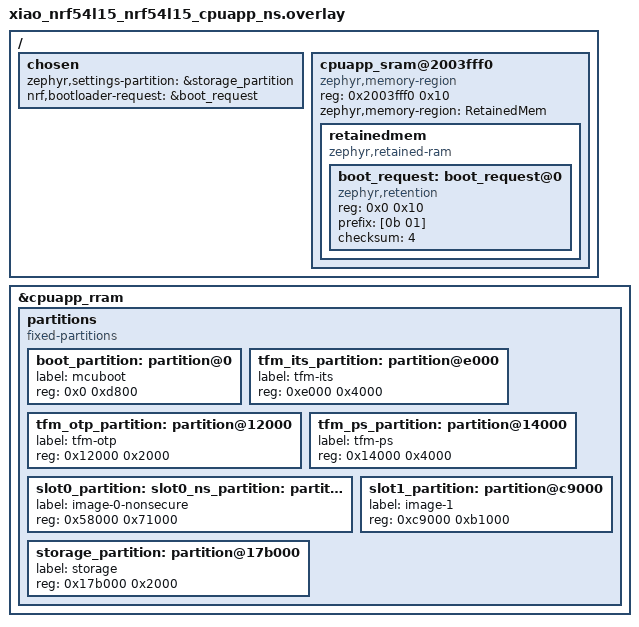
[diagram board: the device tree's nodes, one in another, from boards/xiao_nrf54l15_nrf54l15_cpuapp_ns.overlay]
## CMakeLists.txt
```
#
# Copyright (c) 2026
#
# SPDX-License-Identifier: LicenseRef-Nordic-5-Clause
#

cmake_minimum_required(VERSION 3.20.0)

find_package(Zephyr REQUIRED HINTS $ENV{ZEPHYR_BASE})
project(sap_demo)

target_sources(app PRIVATE
  src/main.c
  src/demo_credentials.c
)

target_sources_ifdef(CONFIG_SAP_ROLE_CENTRAL app PRIVATE src/sap_central.c)
target_sources_ifdef(CONFIG_SAP_ROLE_PERIPHERAL app PRIVATE src/sap_peripheral.c)
target_include_directories(app PRIVATE src)

if(CONFIG_SAP_DEMO_DFU_CLIENT)
  target_include_directories(app PRIVATE
    ${ZEPHYR_BASE}/subsys/mgmt/mcumgr/util/include
  )
  target_sources(app PRIVATE
    ${ZEPHYR_BASE}/subsys/mgmt/mcumgr/util/src/zcbor_bulk.c
  )
endif()

if(CONFIG_SAP_DEMO_DFU_SERVER AND CONFIG_NRF_MCUBOOT_BOOT_REQUEST)
  target_include_directories(app PRIVATE
    ${WEST_TOPDIR}/bootloader/mcuboot/boot/bootutil/include
    ${WEST_TOPDIR}/bootloader/mcuboot/boot/zephyr/include
  )
endif()
```

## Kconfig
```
#
# Copyright (c) 2026
#
# SPDX-License-Identifier: LicenseRef-Nordic-5-Clause
#

# Work around Kconfig's lack of commas in macro arguments.
DT_CHOSEN_Z_SHELL_UART := zephyr,shell-uart

mainmenu "Secure Application Pairing Demo"

source "Kconfig.zephyr"

menu "SAP demo configuration"

choice SAP_ROLE
	prompt "SAP role"
	default SAP_ROLE_CENTRAL

config SAP_ROLE_CENTRAL
	bool "Root node"
	select BT_CENTRAL
	select BT_OBSERVER
	select BT_GATT_CLIENT
	select BT_GATT_DM
	select BT_PERIPHERAL

config SAP_ROLE_PERIPHERAL
	bool "Leaf node"
	select BT_PERIPHERAL

endchoice

config SAP_EXPECTED_GROUP_ID
	hex "Expected SAP group identifier"
	default 0x2A

config SAP_ALLOWED_CENTRAL_ID
	int "Allowed central device identifier"
	range 0 255
	default 0

config SAP_UPSTREAM_ALLOWED_CENTRAL_ID
	int "Allowed upstream controller identifier"
	range 0 255
	default 42
	depends on SAP_ROLE_CENTRAL
	help
	  Device identifier that the root node accepts on its upstream SAP
	  controller link. The default is used by the Bleak host demo script.

config SAP_REQUIRE_BLE_ENCRYPTION
	bool "Require BLE link encryption before SAP"
	default n if BOARD_NRF54L15BSIM
	default y
	help
	  Keep BLE SMP/link encryption as a prerequisite for SAP when the target
	  supports it reliably. On the nrf54l15bsim sample target this defaults
	  to disabled because local BabbleSim validation could not complete the
	  BLE security procedure reliably on that simulator target. The sample
	  still exercises SAP mutual authentication and SAP-level AES-CCM
	  transport protection there.

config SAP_UPSTREAM_REQUIRE_BLE_ENCRYPTION
	bool "Require BLE link encryption on the root upstream controller link"
	depends on SAP_ROLE_CENTRAL
	default y
	help
	  Keep BLE SMP/link encryption as a prerequisite for the root node's
	  upstream SAP controller link. Disable this only for interop demos where
	  the external controller stack cannot complete BLE security reliably and
	  you still want to demonstrate SAP mutual authentication plus SAP-level
	  encrypted transport on that upstream link.

config SAP_USE_BLE_SC_OOB_PAIRING
	bool "Use in-band exchanged BLE Secure Connections OOB for post-auth transport"
	depends on BT_SMP
	default n
	help
	  Prototype a CBAP-like transport flow for root-to-leaf links. SAP still
	  performs certificate-based authentication, but the authenticated nodes
	  exchange LE Secure Connections OOB data during the SAP handshake, then
	  upgrade the BLE link to Security Level 4 and rely on the BLE stack for
	  transport encryption. SAP application payloads then travel as plaintext
	  over the authenticated encrypted BLE link instead of using SAP AES-CCM
	  on every packet. The root's upstream controller link remains on the
	  original SAP encrypted transport path.

config SAP_SHELL
	bool "Enable SAP shell commands"
	default y if !BOARD_NRF54L15BSIM
	default n if BOARD_NRF54L15BSIM
	select SHELL
	select SHELL_VT100_COLORS
	depends on $(dt_chosen_enabled,$(DT_CHOSEN_Z_SHELL_UART)) || BOARD_NRF54L15BSIM
	help
	  Enable a UART shell with SAP demo commands. The central build can list
	  peers and send secure text to one peer or all peers. The peripheral
	  build can send secure text to the connected central. Boards without a
	  non-secure ``zephyr,shell-uart`` chosen node leave the shell disabled
	  by default so the demo can still run without a UART.

if SAP_SHELL

config SHELL_STACK_SIZE
	default 8192

config SHELL_CMD_BUFF_SIZE
	default 256

config SHELL_ARGC_MAX
	default 16

config SHELL_BACKEND_SERIAL_TX_RING_BUFFER_SIZE
	default 1024

endif

config SAP_DK_IO
	bool "Enable DK button and LED demo IO"
	depends on BOARD_NRF54L15DK_NRF54L15_CPUAPP || \
		BOARD_NRF54L15DK_NRF54L15_CPUAPP_NS
	default y
	select DK_LIBRARY
	help
	  Enable the Nordic DK buttons and LEDs for the SAP demo. On the
	  peripheral, Button 1 sends a secure button-state event. On the
	  central, peripherals 1..4 map to LEDs 1..4. Additional peripherals
	  remain authenticated but do not receive an LED assignment.

config SAP_DEMO_PERIPHERAL_ID
	int "Hardware peripheral device identifier"
	depends on SAP_ROLE_PERIPHERAL && !BOARD_NRF54L15BSIM
	range 1 4
	default 1
	help
	  Select which demo peripheral credential this hardware build should use.
	  The sample contains four provisioned peripheral identities with device
	  IDs 1..4. Build each real peripheral with a different value so the
	  central can authenticate and track them as distinct SAP peers.

config SAP_DEMO_GATED_DFU_SERVICE
	bool "Expose gated MCUmgr DFU SMP service after SAP"
	default y if !BOARD_NRF54L15BSIM
	default n if BOARD_NRF54L15BSIM
	help
	  Demonstrate how SAP can hide the standard Bluetooth MCUmgr SMP/DFU
	  service until application-layer authentication succeeds. On hardware,
	  the central then verifies the service by sending an MCUmgr OS echo
	  request after SAP completes.

config SAP_DEMO_DFU_CLIENT
	bool
	default y if SAP_ROLE_CENTRAL && SAP_DEMO_GATED_DFU_SERVICE
	select BT_DFU_SMP
	select ZCBOR

config SAP_DEMO_DFU_SERVER
	bool
	default y if SAP_ROLE_PERIPHERAL && SAP_DEMO_GATED_DFU_SERVICE
	select CRC
	select IMG_MANAGER
	select MCUMGR
	select MCUMGR_GRP_IMG
	select MCUMGR_GRP_OS
	select MCUMGR_TRANSPORT_BT
	select MCUMGR_TRANSPORT_BT_DYNAMIC_SVC_REGISTRATION
	select NET_BUF
	select STREAM_FLASH
	select ZCBOR

config SAP_DEMO_LED_PATTERN_ID
	int "Leaf status LED pattern identifier"
	range 1 2
	default 1
	depends on SAP_ROLE_PERIPHERAL
	help
	  Distinguishes visible leaf firmware variants for the DFU demo. Pattern
	  1 is the default image. Pattern 2 is intended for the post-DFU image
	  so the result is obvious on-device.

endmenu
```

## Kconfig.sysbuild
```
#
# Copyright (c) 2026
#
# SPDX-License-Identifier: LicenseRef-Nordic-5-Clause
#

choice BOOTLOADER
	default BOOTLOADER_MCUBOOT if BOARD_XIAO_NRF54L15
endchoice

if BOOTLOADER_MCUBOOT

choice MCUBOOT_MODE
	default MCUBOOT_MODE_DIRECT_XIP if BOARD_XIAO_NRF54L15
endchoice

config PM_EXTERNAL_FLASH_MCUBOOT_SECONDARY
	default y if BOARD_NRF54L15DK

config PM_OVERRIDE_EXTERNAL_DRIVER_CHECK
	default y if BOARD_NRF54L15DK

endif

source "share/sysbuild/Kconfig"
```

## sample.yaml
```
sample:
  name: Secure Application Pairing
tests:
  sample.bluetooth.sap.central:
    build_only: true
    platform_allow:
      - nrf54l15bsim/nrf54l15/cpuapp
      - nrf54l15dk/nrf54l15/cpuapp
      - nrf54l15dk/nrf54l15/cpuapp/ns
      - xiao_nrf54l15/nrf54l15/cpuapp
      - xiao_nrf54l15/nrf54l15/cpuapp/ns
    integration_platforms:
      - nrf54l15bsim/nrf54l15/cpuapp
      - nrf54l15dk/nrf54l15/cpuapp
      - nrf54l15dk/nrf54l15/cpuapp/ns
      - xiao_nrf54l15/nrf54l15/cpuapp
      - xiao_nrf54l15/nrf54l15/cpuapp/ns
    tags:
      - bluetooth
      - crypto
  sample.bluetooth.sap.peripheral:
    build_only: true
    extra_args: EXTRA_CONF_FILE=peripheral.conf
    platform_allow:
      - nrf54l15bsim/nrf54l15/cpuapp
      - nrf54l15dk/nrf54l15/cpuapp
      - nrf54l15dk/nrf54l15/cpuapp/ns
      - xiao_nrf54l15/nrf54l15/cpuapp
      - xiao_nrf54l15/nrf54l15/cpuapp/ns
    integration_platforms:
      - nrf54l15bsim/nrf54l15/cpuapp
      - nrf54l15dk/nrf54l15/cpuapp
      - nrf54l15dk/nrf54l15/cpuapp/ns
      - xiao_nrf54l15/nrf54l15/cpuapp
      - xiao_nrf54l15/nrf54l15/cpuapp/ns
    tags:
      - bluetooth
      - crypto
```

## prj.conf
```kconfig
#
# Copyright (c) 2026
#
# SPDX-License-Identifier: LicenseRef-Nordic-5-Clause
#

CONFIG_SYS_CLOCK_TICKS_PER_SEC=1000

CONFIG_SAP=y
CONFIG_BT=y
CONFIG_BT_SMP=y
CONFIG_BT_SMP_ENFORCE_MITM=n
CONFIG_BT_PRIVACY=y
CONFIG_BT_DEVICE_NAME="SAP"
CONFIG_BT_DEVICE_NAME_DYNAMIC=y
CONFIG_BT_MAX_CONN=4
CONFIG_BT_MAX_PAIRED=8
CONFIG_BT_RX_STACK_SIZE=8192
CONFIG_BT_LONG_WQ_STACK_SIZE=4096
CONFIG_BT_L2CAP_TX_MTU=300
CONFIG_BT_L2CAP_TX_FRAG_COUNT=6
CONFIG_BT_BUF_ACL_RX_SIZE=304
CONFIG_BT_BUF_ACL_TX_SIZE=251
CONFIG_BT_GATT_DYNAMIC_DB=y
CONFIG_BT_GATT_SERVICE_CHANGED=y

CONFIG_LOG=y
CONFIG_LOG_MODE_IMMEDIATE=y

CONFIG_FLASH=y
CONFIG_FLASH_PAGE_LAYOUT=y
CONFIG_FLASH_MAP=y
CONFIG_NVS=y
CONFIG_SETTINGS=y
CONFIG_SETTINGS_NVS=y
CONFIG_BT_SETTINGS=y

CONFIG_MAIN_STACK_SIZE=8192
CONFIG_SYSTEM_WORKQUEUE_STACK_SIZE=4096
CONFIG_SHELL_STACK_SIZE=8192
CONFIG_HEAP_MEM_POOL_SIZE=16384

CONFIG_ENTROPY_GENERATOR=y
CONFIG_MBEDTLS=y
CONFIG_MBEDTLS_PSA_CRYPTO_C=y
CONFIG_PSA_CRYPTO=y
CONFIG_PSA_WANT_GENERATE_RANDOM=y
CONFIG_PSA_WANT_ALG_SHA_256=y
CONFIG_PSA_WANT_ALG_ECDSA=y
CONFIG_PSA_WANT_ALG_ECDH=y
CONFIG_PSA_WANT_ALG_HKDF=y
CONFIG_PSA_WANT_ALG_HMAC=y
CONFIG_PSA_WANT_ALG_CCM=y
CONFIG_PSA_WANT_KEY_TYPE_AES=y
CONFIG_PSA_WANT_KEY_TYPE_DERIVE=y
CONFIG_PSA_WANT_KEY_TYPE_RAW_DATA=y
CONFIG_PSA_WANT_KEY_TYPE_ECC_PUBLIC_KEY=y
CONFIG_PSA_WANT_KEY_TYPE_ECC_KEY_PAIR_IMPORT=y
CONFIG_PSA_WANT_KEY_TYPE_ECC_KEY_PAIR_GENERATE=y
CONFIG_PSA_WANT_KEY_TYPE_ECC_KEY_PAIR_EXPORT=y
CONFIG_PSA_WANT_ECC_SECP_R1_256=y

# Route /ns reboots through TF-M so MCUboot sees a real global reset.
# CONFIG_TFM_ALLOW_NON_SECURE_RESET is not set
```

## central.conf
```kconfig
CONFIG_SAP_ROLE_CENTRAL=y
CONFIG_BT_MAX_CONN=6
CONFIG_SAP_MAX_PEERS=4
```

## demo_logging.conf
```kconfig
CONFIG_SAP_DEMO_LOGGING=y
CONFIG_LOG_MODE_IMMEDIATE=n
CONFIG_LOG_MODE_DEFERRED=y
CONFIG_LOG_PROCESS_THREAD_STACK_SIZE=4096
CONFIG_THREAD_NAME=y
```

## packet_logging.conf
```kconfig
CONFIG_SAP_PACKET_LOGGING=y
CONFIG_LOG_BUFFER_SIZE=32768
```

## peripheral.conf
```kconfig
CONFIG_SAP_ROLE_PERIPHERAL=y
CONFIG_BT_MAX_CONN=1
CONFIG_SAP_MAX_PEERS=1
CONFIG_MCUMGR_TRANSPORT_BT_PERM_RW_ENCRYPT=y
CONFIG_MCUBOOT_BOOTUTIL_LIB=y
CONFIG_MCUBOOT_SIGNATURE_KEY_FILE="bootloader/mcuboot/root-rsa-2048.pem"
CONFIG_MCUBOOT_IMGTOOL_SIGN_VERSION="1.0.0+0"
CONFIG_MCUMGR_GRP_IMG_ALLOW_CONFIRM_NON_ACTIVE_IMAGE_ANY=y
CONFIG_MCUMGR_TRANSPORT_WORKQUEUE_STACK_SIZE=6144
CONFIG_IMG_ENABLE_IMAGE_CHECK=y
CONFIG_RETAINED_MEM=y
CONFIG_RETENTION=y
CONFIG_NRF_MCUBOOT_BOOT_REQUEST=y
CONFIG_NCS_MCUBOOT_BOOT_REQUEST_TEST_SETS_BOOT_PREFERENCE=y
```

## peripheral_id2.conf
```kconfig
CONFIG_SAP_DEMO_PERIPHERAL_ID=2
```

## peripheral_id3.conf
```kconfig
CONFIG_SAP_DEMO_PERIPHERAL_ID=3
```

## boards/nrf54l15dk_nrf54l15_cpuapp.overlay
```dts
/*
 * Copyright (c) 2026
 *
 * SPDX-License-Identifier: LicenseRef-Nordic-5-Clause
 */

/ {
	aliases {
		watchdog0 = &wdt31;
	};

	chosen {
		nordic,pm-ext-flash = &mx25r64;
	};
};

&cpuapp_rram {
	reg = <0x0 DT_SIZE_K(1524)>;
};

&cpuapp_sram {
	reg = <0x20000000 DT_SIZE_K(256)>;
	ranges = <0x0 0x20000000 0x40000>;
};

&mx25r64 {
	status = "okay";
};

&wdt31 {
	status = "okay";
};
```

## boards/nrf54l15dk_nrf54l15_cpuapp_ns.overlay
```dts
/*
 * Copyright (c) 2026
 *
 * SPDX-License-Identifier: LicenseRef-Nordic-5-Clause
 */

/ {
	aliases {
		watchdog0 = &wdt31;
	};

	chosen {
		nordic,pm-ext-flash = &mx25r64;
	};
};

&cpuapp_rram {
	reg = <0x0 DT_SIZE_K(1524)>;
};

&cpuapp_sram {
	reg = <0x20000000 DT_SIZE_K(256)>;
	ranges = <0x0 0x20000000 0x40000>;
};

&mx25r64 {
	status = "okay";
};

&wdt31 {
	status = "okay";
};

/* TF-M reserves the secure IRQ numbers for these GPIOTE instances. */
&gpiote20 {
	interrupts = <218 NRF_DEFAULT_IRQ_PRIORITY>;
};

&gpiote30 {
	interrupts = <268 NRF_DEFAULT_IRQ_PRIORITY>;
};
```

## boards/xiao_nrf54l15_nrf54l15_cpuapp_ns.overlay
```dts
/ {
	chosen {
		zephyr,settings-partition = &storage_partition;
		nrf,bootloader-request = &boot_request;
	};

	cpuapp_sram@2003fff0 {
		compatible = "zephyr,memory-region", "mmio-sram";
		reg = <0x2003fff0 0x10>;
		zephyr,memory-region = "RetainedMem";
		status = "okay";

		retainedmem {
			compatible = "zephyr,retained-ram";
			status = "okay";
			#address-cells = <1>;
			#size-cells = <1>;

			boot_request: boot_request@0 {
				compatible = "zephyr,retention";
				status = "okay";
				reg = <0x0 0x10>;
				prefix = [0b 01];
				checksum = <4>;
			};
		};
	};
};

&cpuapp_rram {
	/delete-node/ partitions;

	partitions {
		compatible = "fixed-partitions";
		#address-cells = <1>;
		#size-cells = <1>;

		boot_partition: partition@0 {
			label = "mcuboot";
			reg = <0x0 0xd800>;
		};

		tfm_its_partition: partition@e000 {
			label = "tfm-its";
			reg = <0xe000 0x4000>;
		};

		tfm_otp_partition: partition@12000 {
			label = "tfm-otp";
			reg = <0x12000 0x2000>;
		};

		tfm_ps_partition: partition@14000 {
			label = "tfm-ps";
			reg = <0x14000 0x4000>;
		};

		slot0_partition: slot0_ns_partition: partition@58000 {
			label = "image-0-nonsecure";
			reg = <0x58000 0x71000>;
		};

		slot1_partition: partition@c9000 {
			label = "image-1";
			reg = <0xc9000 0xb1000>;
		};

		storage_partition: partition@17b000 {
			label = "storage";
			reg = <0x17b000 0x2000>;
		};
	};
};
```

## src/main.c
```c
/*
 * Copyright (c) 2026
 *
 * SPDX-License-Identifier: LicenseRef-Nordic-5-Clause
 */

#include <stdio.h>

#include <zephyr/kernel.h>
#include <zephyr/bluetooth/bluetooth.h>
#include <zephyr/bluetooth/conn.h>
#include <zephyr/logging/log.h>
#include <zephyr/settings/settings.h>
#if defined(CONFIG_MCUBOOT_BOOTUTIL_LIB)
#include <zephyr/dfu/mcuboot.h>
#endif
#include <zephyr/sys/printk.h>

#include <sap/sap_service.h>
#include <sap/sap_trace.h>

#include "demo_credentials.h"

LOG_MODULE_REGISTER(sap_main, CONFIG_SAP_LOG_LEVEL);

volatile uint32_t sap_boot_stage;
volatile int sap_boot_err;

#if defined(CONFIG_SAP_ROLE_CENTRAL)
int sap_central_run(const struct sap_policy *policy);
#endif

#if defined(CONFIG_SAP_ROLE_PERIPHERAL)
int sap_peripheral_run(const struct sap_policy *policy);
#endif

static void set_name(enum sap_role role, const struct sap_device_credential *credential)
{
	char name[24];
	int err;

	snprintk(name, sizeof(name), "SAP-%c-%u",
		 (role == SAP_ROLE_CENTRAL) ? 'C' : 'P',
		 credential->cert.body.device_id);

	err = bt_set_name(name);
	if (err != 0) {
		LOG_WRN("Failed to set dynamic device name (%d)", err);
	}
}

static void pairing_complete(struct bt_conn *conn, bool bonded)
{
	struct bt_conn_info info;
	int err;

	err = bt_conn_get_info(conn, &info);
	if (err == 0) {
		LOG_INF("BLE pairing complete: bonded=%u level=%u key_size=%u",
			bonded, info.security.level, info.security.enc_key_size);
		return;
	}

	LOG_INF("BLE pairing complete: bonded=%u", bonded);
}

static void pairing_failed(struct bt_conn *conn, enum bt_security_err err)
{
	ARG_UNUSED(conn);
	LOG_ERR("BLE pairing failed: %d %s", err, bt_security_err_to_str(err));
}

static struct bt_conn_auth_info_cb auth_info_cb = {
	.pairing_complete = pairing_complete,
	.pairing_failed = pairing_failed,
};

int main(void)
{
	enum sap_role role = IS_ENABLED(CONFIG_SAP_ROLE_CENTRAL) ?
		SAP_ROLE_CENTRAL : SAP_ROLE_PERIPHERAL;
	const struct sap_device_credential *local_credential;
	struct sap_policy policy;
	size_t ca_len;
	int err;

	local_credential = demo_credentials_select(role);
	printk("SAPDBG main role=%u device_id=%u\n", role, local_credential->cert.body.device_id);
	sap_boot_stage = 1U;
	sap_boot_err = 0;
	memset(&policy, 0, sizeof(policy));
	policy.local_credential = local_credential;
	policy.ca_public_key = demo_credentials_ca_public_key(&ca_len);
	policy.ca_public_key_len = ca_len;
	policy.expected_group_id = CONFIG_SAP_EXPECTED_GROUP_ID;
	policy.allowed_central_id = CONFIG_SAP_ALLOWED_CENTRAL_ID;
	policy.require_ble_encryption =
		IS_ENABLED(CONFIG_SAP_REQUIRE_BLE_ENCRYPTION) &&
		!IS_ENABLED(CONFIG_SAP_USE_BLE_SC_OOB_PAIRING);
	policy.use_ble_sc_oob_pairing = IS_ENABLED(CONFIG_SAP_USE_BLE_SC_OOB_PAIRING);
	policy.use_link_security_for_secure_transport =
		IS_ENABLED(CONFIG_SAP_USE_BLE_SC_OOB_PAIRING);

	err = bt_enable(NULL);
	printk("SAPDBG bt_enable err=%d\n", err);
	if (err != 0) {
		sap_boot_err = err;
		LOG_ERR("Bluetooth init failed (%d)", err);
		return 0;
	}
	sap_boot_stage = 2U;

	if (IS_ENABLED(CONFIG_SETTINGS)) {
		err = settings_load();
		if (err != 0) {
			sap_boot_err = err;
			LOG_WRN("Settings load failed (%d), continuing without persisted state",
				err);
		} else {
			if (IS_ENABLED(CONFIG_SAP_DEMO_LOGGING)) {
				SAP_TRACE("FLOW 0/8 Bluetooth settings restored from NVS");
			}
		}
	}
	sap_boot_stage = 3U;

	if (IS_ENABLED(CONFIG_MCUBOOT_BOOTUTIL_LIB) &&
	    IS_ENABLED(CONFIG_MCUBOOT_IMG_MANAGER) &&
	    !boot_is_img_confirmed()) {
		err = boot_write_img_confirmed();
		if (err != 0) {
			LOG_WRN("Failed to confirm running MCUboot image (%d)", err);
		} else {
			LOG_INF("Confirmed running MCUboot image");
		}
	}

	err = bt_conn_auth_info_cb_register(&auth_info_cb);
	printk("SAPDBG auth_info_cb_register err=%d\n", err);
	if (err != 0) {
		sap_boot_err = err;
		LOG_ERR("Failed to register pairing diagnostics (%d)", err);
		return 0;
	}
	sap_boot_stage = 4U;

	set_name(role, local_credential);
	printk("SAPDBG set_name done role=%u\n", role);

	LOG_INF("SAP sample starting as %s, local device id %u",
		(role == SAP_ROLE_CENTRAL) ? "central" : "peripheral",
		local_credential->cert.body.device_id);
	if (IS_ENABLED(CONFIG_SAP_DEMO_LOGGING)) {
		SAP_TRACE("FLOW 0/8 local policy: group=0x%02x allowed_central=%u ble_encryption=%u",
			  policy.expected_group_id, policy.allowed_central_id,
			  policy.require_ble_encryption);
	}

	if (IS_ENABLED(CONFIG_SAP_REQUIRE_BLE_ENCRYPTION) &&
	    IS_ENABLED(CONFIG_BOARD_NRF54L15BSIM)) {
		LOG_WRN("BLE encryption is enabled on nrf54l15bsim even though local BabbleSim validation is not reliable");
	}

#if defined(CONFIG_SAP_ROLE_CENTRAL)
	sap_boot_stage = 5U;
	printk("SAPDBG entering central run\n");
	return sap_central_run(&policy);
#else
	sap_boot_stage = 5U;
	printk("SAPDBG entering peripheral run\n");
	return sap_peripheral_run(&policy);
#endif
}
```

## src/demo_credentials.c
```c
/*
 * Copyright (c) 2026
 *
 * SPDX-License-Identifier: LicenseRef-Nordic-5-Clause
 */

#include <zephyr/kernel.h>

#include "demo_credentials.h"

#if defined(CONFIG_BOARD_NRF54L15BSIM)
extern unsigned int bsim_args_get_global_device_nbr(void);
#endif

static const uint8_t sap_ca_public_key[SAP_IDENTITY_PUBLIC_KEY_LEN] = {
	0x04, 0x8d, 0x3f, 0x73, 0x9d, 0x0b, 0xef, 0x0d,
	0xc2, 0x67, 0x6e, 0x47, 0x10, 0xa9, 0xc8, 0xeb,
	0xaf, 0x1b, 0x33, 0xb7, 0xca, 0x73, 0xe9, 0x03,
	0x27, 0x84, 0x01, 0x1a, 0x7b, 0xce, 0x23, 0x65,
	0x1e, 0x66, 0xa2, 0xec, 0x87, 0x2f, 0x79, 0x09,
	0x20, 0xc2, 0x9d, 0x9f, 0x76, 0x4c, 0xf1, 0xc7,
	0x71, 0x08, 0x55, 0x60, 0x31, 0xb3, 0xad, 0x71,
	0x16, 0x4e, 0xc0, 0xcf, 0x56, 0xe1, 0x68, 0x3a,
	0x87,
};

#define SAP_GROUP_ID 0x2A

static const struct sap_device_credential central_credentials[] = {
	{
		.simulated_device_number = 0,
		.private_key = {
			0x79, 0xf7, 0x7d, 0x57, 0xf9, 0x6a, 0x0b, 0xd1,
			0x1a, 0xf3, 0xc3, 0x97, 0x9e, 0xe3, 0x37, 0x77,
			0xd2, 0x89, 0x73, 0xf7, 0xf1, 0x24, 0xe0, 0x23,
			0xd5, 0x84, 0x45, 0x32, 0x69, 0x50, 0x91, 0xaf,
		},
		.cert = {
			.body = {
				.version = SAP_VERSION,
				.role_mask = 3,
				.device_id = 0,
				.group_id = SAP_GROUP_ID,
				.public_key = {
			0x04, 0xf9, 0xb3, 0xf7, 0xcd, 0xe4, 0x8e, 0x71,
			0xc6, 0x02, 0xfc, 0xe9, 0x29, 0x47, 0x3c, 0x42,
			0xe4, 0x5b, 0xd4, 0xb4, 0x7e, 0xff, 0x85, 0x95,
			0x6e, 0xe5, 0x40, 0x45, 0x8b, 0x9e, 0xc2, 0x0a,
			0x8f, 0x29, 0xc8, 0x8d, 0x70, 0xd1, 0x38, 0x69,
			0x69, 0xdc, 0x3f, 0xb7, 0x48, 0xa0, 0x1c, 0xdf,
			0x08, 0x0e, 0x43, 0xd5, 0xcd, 0x23, 0xc0, 0x26,
			0xf1, 0x46, 0x45, 0xae, 0x25, 0x15, 0x89, 0xa4,
			0x30,
				},
			},
			.ca_signature = {
			0x12, 0x4f, 0xb4, 0x13, 0x6c, 0x58, 0x8d, 0x19,
			0x1a, 0x89, 0xaa, 0x86, 0x98, 0xda, 0x7c, 0x19,
			0x89, 0xdb, 0x31, 0x21, 0xa3, 0xbf, 0x97, 0x36,
			0x71, 0xa3, 0x9f, 0x65, 0x95, 0x33, 0x09, 0x19,
			0x7f, 0x0d, 0xf3, 0xc3, 0xa4, 0x3d, 0xce, 0x02,
			0xe1, 0xd4, 0xd5, 0xfe, 0x99, 0x37, 0xb3, 0xea,
			0x4c, 0x88, 0x3b, 0x99, 0xde, 0x35, 0x62, 0xcb,
			0x2c, 0x9a, 0xe2, 0xa0, 0x8a, 0xc4, 0xcb, 0x6b,
			},
		},
	}
};

static const struct sap_device_credential peripheral_credentials[] = {
	{
		.simulated_device_number = 1,
		.private_key = {
			0x03, 0x11, 0x24, 0xa4, 0xbe, 0x9e, 0xf4, 0xea,
			0x15, 0xd7, 0xce, 0x4a, 0x87, 0x45, 0x5a, 0x88,
			0x69, 0x65, 0x69, 0x99, 0x85, 0x62, 0xdc, 0x19,
			0x1b, 0xd0, 0x21, 0x3e, 0xb0, 0xc7, 0xea, 0xa6,
		},
		.cert = {
			.body = {
				.version = SAP_VERSION,
				.role_mask = 2,
				.device_id = 1,
				.group_id = SAP_GROUP_ID,
				.public_key = {
			0x04, 0x9e, 0x81, 0x2d, 0xb0, 0xa0, 0xda, 0x17,
			0x26, 0x63, 0xe3, 0x6a, 0x50, 0xd4, 0x92, 0x19,
			0x46, 0x45, 0xf1, 0x1e, 0x31, 0x9e, 0xfe, 0xe3,
			0x38, 0xc3, 0x7d, 0x05, 0xa0, 0x69, 0x22, 0x7a,
			0xf6, 0xfb, 0x8d, 0xe6, 0x4c, 0xaa, 0x04, 0xa7,
			0x28, 0xee, 0xb3, 0xcd, 0xec, 0x98, 0xfb, 0xed,
			0x2b, 0x91, 0x80, 0x7a, 0xbc, 0xbb, 0xe0, 0x90,
			0x1a, 0xcf, 0x60, 0x20, 0x4d, 0xa9, 0x52, 0x13,
			0x99,
				},
			},
			.ca_signature = {
			0x79, 0x96, 0xb9, 0x70, 0xf9, 0xfc, 0x16, 0x7f,
			0x9f, 0x69, 0x09, 0x43, 0x54, 0x28, 0xca, 0x15,
			0xac, 0x1b, 0xc1, 0x15, 0xa8, 0xf9, 0x35, 0x13,
			0xa1, 0x06, 0x94, 0xd3, 0xbb, 0x96, 0x91, 0x1a,
			0x7b, 0x94, 0x9d, 0x0a, 0x93, 0x13, 0x9b, 0x05,
			0x82, 0x4d, 0x21, 0xae, 0x88, 0x62, 0xb1, 0xa9,
			0x80, 0xa4, 0xb0, 0xcb, 0xdd, 0x9d, 0xa9, 0x45,
			0xe8, 0x45, 0x60, 0xb3, 0xf0, 0x60, 0x29, 0x23,
			},
		},
	},
	{
		.simulated_device_number = 2,
		.private_key = {
			0x4f, 0x8e, 0x5a, 0x97, 0xe7, 0xc6, 0xe5, 0x8c,
			0x4f, 0xf0, 0xf8, 0x58, 0x03, 0x73, 0xdb, 0xfa,
			0xd5, 0x95, 0xbf, 0x1f, 0xf2, 0x5a, 0x4e, 0xdf,
			0x97, 0xe3, 0xc4, 0x47, 0x62, 0xeb, 0x17, 0xae,
		},
		.cert = {
			.body = {
				.version = SAP_VERSION,
				.role_mask = 2,
				.device_id = 2,
				.group_id = SAP_GROUP_ID,
				.public_key = {
			0x04, 0x12, 0x39, 0x0d, 0xf0, 0x3b, 0xa4, 0xb9,
			0x4f, 0x8a, 0xf0, 0x1b, 0x3f, 0x65, 0xd0, 0x6e,
			0x6c, 0xcd, 0xed, 0xd2, 0x3a, 0xce, 0x0b, 0xf9,
			0x42, 0x80, 0x87, 0x76, 0x5a, 0x39, 0x35, 0x2f,
			0xda, 0x9a, 0xea, 0x08, 0xfa, 0xc9, 0x74, 0xba,
			0xd8, 0x65, 0x7b, 0x52, 0x03, 0x2c, 0x91, 0x26,
			0xf5, 0x02, 0x1f, 0x0a, 0xdb, 0xc7, 0x41, 0x72,
			0xbd, 0xde, 0x89, 0x70, 0xbc, 0xca, 0x22, 0xd6,
			0x3f,
				},
			},
			.ca_signature = {
			0xd3, 0xea, 0x56, 0xa6, 0x44, 0xd8, 0xc8, 0x94,
			0x30, 0x8d, 0x08, 0x32, 0x45, 0x40, 0x29, 0x79,
			0xcc, 0xac, 0x91, 0x4c, 0x56, 0xe3, 0xe0, 0x10,
			0x6f, 0xcc, 0x23, 0x84, 0x49, 0x1b, 0x63, 0x8e,
			0xe0, 0x4e, 0xe4, 0xcd, 0x5e, 0x07, 0x9f, 0x30,
			0x05, 0xeb, 0xda, 0x18, 0x7d, 0x78, 0x80, 0xa6,
			0xae, 0xc7, 0xd0, 0x35, 0xd1, 0x54, 0xba, 0xcb,
			0xe8, 0xaa, 0xf8, 0x80, 0xd9, 0xa1, 0x7a, 0x08,
			},
		},
	},
	{
		.simulated_device_number = 3,
		.private_key = {
			0x93, 0xff, 0x23, 0xdc, 0x67, 0xf5, 0xcd, 0x1c,
			0xb9, 0xbe, 0x39, 0xfb, 0xa6, 0xf4, 0xba, 0x49,
			0x1b, 0xac, 0xc4, 0x46, 0xae, 0x13, 0x70, 0xc2,
			0x42, 0x87, 0x78, 0x62, 0xad, 0x62, 0x43, 0x27,
		},
		.cert = {
			.body = {
				.version = SAP_VERSION,
				.role_mask = 2,
				.device_id = 3,
				.group_id = SAP_GROUP_ID,
				.public_key = {
			0x04, 0x74, 0x82, 0x96, 0x2a, 0x7e, 0x3a, 0x91,
			0x3a, 0xa1, 0x5f, 0xe9, 0x20, 0x9e, 0x1d, 0x5f,
			0xca, 0x1f, 0x79, 0x20, 0x45, 0x6c, 0x88, 0x95,
			0x71, 0xdb, 0x07, 0x45, 0x74, 0x6c, 0xa9, 0xff,
			0x2a, 0xd3, 0x8e, 0x5a, 0xd9, 0x28, 0xc8, 0x23,
			0x7e, 0x5e, 0xb4, 0x0a, 0xcd, 0x11, 0xc3, 0x6f,
			0xa3, 0xff, 0x15, 0xfe, 0x94, 0x8f, 0x6c, 0x16,
			0xa2, 0x0f, 0xca, 0xcc, 0x76, 0xe5, 0xb2, 0x9a,
			0x2b,
				},
			},
			.ca_signature = {
			0x2f, 0xf8, 0x52, 0x03, 0x30, 0x93, 0xf8, 0x76,
			0x50, 0x1b, 0xe5, 0x5b, 0x41, 0x43, 0xea, 0xdc,
			0x90, 0x2a, 0xf1, 0xef, 0x7d, 0x16, 0x6c, 0x86,
			0x7c, 0x03, 0x32, 0xf7, 0x97, 0xdf, 0xc9, 0x7d,
			0x3a, 0x56, 0xf8, 0x4c, 0x64, 0xbf, 0x4e, 0xfb,
			0xd2, 0xaf, 0x94, 0x67, 0x89, 0xec, 0x6e, 0x7d,
			0xd8, 0x05, 0x82, 0x28, 0xae, 0x90, 0xc0, 0x3b,
			0x6e, 0x4f, 0x0f, 0x93, 0x88, 0xc2, 0x56, 0xf3,
			},
		},
	},
	{
		.simulated_device_number = 4,
		.private_key = {
			0xdc, 0x8d, 0x04, 0x14, 0xb6, 0x72, 0x68, 0xfe,
			0x81, 0xd8, 0x6d, 0xb7, 0x1f, 0xc6, 0xfd, 0x6e,
			0x68, 0xe8, 0x55, 0x6f, 0x7d, 0x3b, 0x12, 0x64,
			0xbb, 0x25, 0xcb, 0x47, 0x28, 0xd4, 0x05, 0x78,
		},
		.cert = {
			.body = {
				.version = SAP_VERSION,
				.role_mask = 2,
				.device_id = 4,
				.group_id = SAP_GROUP_ID,
				.public_key = {
			0x04, 0x38, 0x80, 0x27, 0xbd, 0x0c, 0x79, 0xcd,
			0xd3, 0x36, 0xcd, 0xc3, 0xdf, 0xeb, 0x03, 0xd1,
			0x95, 0x50, 0x38, 0x0c, 0x72, 0x3d, 0x0f, 0xd0,
			0xe9, 0xc1, 0x7d, 0x49, 0xab, 0xf1, 0xff, 0x51,
			0x3c, 0x2c, 0x17, 0x7c, 0x1d, 0x21, 0xf3, 0xfe,
			0x30, 0xe5, 0x18, 0xb9, 0x0b, 0x29, 0x26, 0x8b,
			0x93, 0x95, 0xd5, 0x1a, 0x92, 0x1f, 0x34, 0x89,
			0x56, 0xb9, 0x66, 0xf3, 0x35, 0x17, 0xb1, 0x68,
			0xd8,
				},
			},
			.ca_signature = {
			0xea, 0x35, 0x6b, 0xcc, 0xca, 0xd7, 0x07, 0x30,
			0xf4, 0xc9, 0x84, 0x23, 0xc0, 0x1a, 0x13, 0xea,
			0x7e, 0xa1, 0x3b, 0x3e, 0x69, 0xf3, 0xd8, 0x30,
			0xc2, 0x97, 0x08, 0x39, 0xb5, 0x89, 0x3d, 0x05,
			0x83, 0x91, 0xe4, 0x34, 0x57, 0x5d, 0x9b, 0x31,
			0xda, 0xa8, 0x73, 0x97, 0x92, 0x3e, 0x05, 0xb2,
			0x7e, 0x0e, 0xb0, 0x52, 0x0c, 0x4f, 0x9e, 0xf1,
			0x9c, 0x0f, 0x4d, 0x76, 0x46, 0x53, 0x81, 0x9e,
			},
		},
	}
};

static unsigned int simulated_device_number(void)
{
#if defined(CONFIG_BOARD_NRF54L15BSIM)
	return bsim_args_get_global_device_nbr();
#elif defined(CONFIG_SAP_ROLE_PERIPHERAL)
	return CONFIG_SAP_DEMO_PERIPHERAL_ID;
#else
	return 0U;
#endif
}

const struct sap_device_credential *demo_credentials_select(enum sap_role role)
{
	size_t i;
	unsigned int dev_num = simulated_device_number();

	#if !defined(CONFIG_SAP_ROLE_PERIPHERAL)
	ARG_UNUSED(role);
	return &central_credentials[0];
	#endif

	if (role == SAP_ROLE_CENTRAL) {
		return &central_credentials[0];
	}

	for (i = 0; i < ARRAY_SIZE(peripheral_credentials); i++) {
		if (peripheral_credentials[i].simulated_device_number == dev_num) {
			return &peripheral_credentials[i];
		}
	}

	return &peripheral_credentials[0];
}

const uint8_t *demo_credentials_ca_public_key(size_t *len)
{
	if (len != NULL) {
		*len = sizeof(sap_ca_public_key);
	}

	return sap_ca_public_key;
}
```

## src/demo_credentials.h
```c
/*
 * Copyright (c) 2026
 *
 * SPDX-License-Identifier: LicenseRef-Nordic-5-Clause
 */

#ifndef SAP_CREDENTIALS_H__
#define SAP_CREDENTIALS_H__

#include <zephyr/types.h>

#include <sap/sap_service.h>

const struct sap_device_credential *demo_credentials_select(enum sap_role role);
const uint8_t *demo_credentials_ca_public_key(size_t *len);

#endif /* SAP_CREDENTIALS_H__ */
```

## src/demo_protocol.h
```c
/*
 * Copyright (c) 2026
 *
 * SPDX-License-Identifier: LicenseRef-Nordic-5-Clause
 */

#ifndef SAP_DEMO_PROTOCOL_H__
#define SAP_DEMO_PROTOCOL_H__

#include <zephyr/sys/util.h>

#include <sap/sap_protocol.h>

#define BT_UUID_SAP_DEMO_PROTECTED_SERVICE_VAL \
	BT_UUID_128_ENCODE(0x7a18e2d1, 0x3bd2, 0x4f31, 0x8c4b, 0xb6c5b8f7a101)
#define BT_UUID_SAP_DEMO_PROTECTED_STATUS_VAL \
	BT_UUID_128_ENCODE(0x7a18e2d1, 0x3bd2, 0x4f31, 0x8c4b, 0xb6c5b8f7a102)

#define BT_UUID_SAP_DEMO_PROTECTED_SERVICE \
	BT_UUID_DECLARE_128(BT_UUID_SAP_DEMO_PROTECTED_SERVICE_VAL)
#define BT_UUID_SAP_DEMO_PROTECTED_STATUS \
	BT_UUID_DECLARE_128(BT_UUID_SAP_DEMO_PROTECTED_STATUS_VAL)

enum sap_demo_message_type {
	SAP_DEMO_MSG_TEXT = SAP_APP_MSG_TYPE_MIN,
	SAP_DEMO_MSG_BUTTON_STATE,
	SAP_DEMO_MSG_ROOT_STATUS_REQ,
	SAP_DEMO_MSG_ROOT_STATUS_RSP,
	SAP_DEMO_MSG_ROOT_SELECT_LEAF,
	SAP_DEMO_MSG_ROOT_SELECT_RSP,
	SAP_DEMO_MSG_ROOT_DFU_BEGIN,
	SAP_DEMO_MSG_ROOT_DFU_CHUNK,
	SAP_DEMO_MSG_ROOT_DFU_PROGRESS,
	SAP_DEMO_MSG_ROOT_DFU_FINISH,
	SAP_DEMO_MSG_ROOT_DFU_RESULT,
	SAP_DEMO_MSG_DFU_APPLY,
};

enum sap_demo_root_peer_flags {
	SAP_DEMO_ROOT_PEER_AUTHENTICATED = BIT(0),
	SAP_DEMO_ROOT_PEER_PROTECTED_READY = BIT(1),
	SAP_DEMO_ROOT_PEER_DFU_READY = BIT(2),
	SAP_DEMO_ROOT_PEER_SELECTED = BIT(3),
	SAP_DEMO_ROOT_PEER_LED_ASSIGNED = BIT(4),
};

enum sap_demo_root_status_code {
	SAP_DEMO_ROOT_STATUS_OK = 0,
	SAP_DEMO_ROOT_STATUS_INVALID = 1,
	SAP_DEMO_ROOT_STATUS_NO_PEER = 2,
	SAP_DEMO_ROOT_STATUS_BUSY = 3,
	SAP_DEMO_ROOT_STATUS_BAD_STATE = 4,
	SAP_DEMO_ROOT_STATUS_DFU_ERROR = 5,
};

struct sap_demo_root_status_record {
	uint8_t peer_id;
	uint8_t state;
	uint8_t flags;
	uint8_t led_index;
	uint8_t pattern_id;
	uint16_t dfu_chunk_limit_le;
} __packed;

struct sap_demo_root_status_response {
	uint8_t selected_peer_id;
	uint8_t peer_count;
	struct sap_demo_root_status_record records[];
} __packed;

struct sap_demo_root_select_leaf {
	uint8_t peer_id;
} __packed;

struct sap_demo_root_select_response {
	uint8_t status;
	uint8_t selected_peer_id;
} __packed;

struct sap_demo_root_dfu_begin {
	uint8_t peer_id;
	uint8_t image_num;
	uint8_t boot_hash_len;
	uint8_t reserved;
	uint32_t image_size_le;
	uint8_t upload_sha256[32];
	uint8_t boot_hash[64];
} __packed;

struct sap_demo_root_dfu_chunk {
	uint32_t offset_le;
	uint8_t data[];
} __packed;

struct sap_demo_root_dfu_progress {
	uint8_t status;
	uint8_t peer_id;
	uint8_t reserved0;
	uint8_t reserved1;
	uint32_t accepted_offset_le;
	uint32_t image_size_le;
} __packed;

struct sap_demo_root_dfu_finish {
	uint8_t peer_id;
	uint8_t permanent;
} __packed;

struct sap_demo_root_dfu_result {
	uint8_t status;
	uint8_t peer_id;
	uint8_t selected_peer_id;
	uint8_t reserved;
	uint32_t detail_le;
} __packed;

#endif /* SAP_DEMO_PROTOCOL_H__ */
```
